# ATmega1281 register map
Vendor: Atmel; File version: 1.0
CPU: other r0p0, little endian, no MPU, no FPU, 4 interrupt priority bits
Registers are 8-bit, read-write, reset 0x0 unless marked. A register's access mark holds for its fields unless they carry their own. Offsets are from the block's base; [hi:lo] are bit positions.

## TC5 — Timer/Counter, 16-bit
Base 0x0080003A
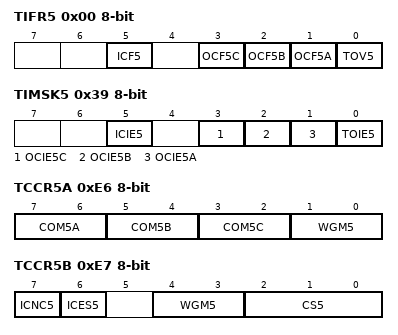
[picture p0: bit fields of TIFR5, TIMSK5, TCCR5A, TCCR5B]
0x00 TIFR5 — Timer/Counter5 Interrupt Flag register (write-only for debugger)
  [5] ICF5 — Input Capture Flag 5
  [3] OCF5C — Output Compare Flag 5C
  [2] OCF5B — Output Compare Flag 5B
  [1] OCF5A — Output Compare Flag 5A
  [0] TOV5 — Timer/Counter5 Overflow Flag
0x39 TIMSK5 — Timer/Counter5 Interrupt Mask Register
  [5] ICIE5 — Timer/Counter5 Input Capture Interrupt Enable
  [3] OCIE5C — Timer/Counter5 Output Compare C Match Interrupt Enable
  [2] OCIE5B — Timer/Counter5 Output Compare B Match Interrupt Enable
  [1] OCIE5A — Timer/Counter5 Output Compare A Match Interrupt Enable
  [0] TOIE5 — Timer/Counter5 Overflow Interrupt Enable
0xE6 TCCR5A — Timer/Counter5 Control Register A
  [7:6] COM5A — Compare Output Mode 1A, bits
  [5:4] COM5B — Compare Output Mode 5B, bits
  [3:2] COM5C — Compare Output Mode 5C, bits
  [1:0] WGM5 — Waveform Generation Mode
0xE7 TCCR5B — Timer/Counter5 Control Register B
  [7] ICNC5 — Input Capture 5 Noise Canceler
  [6] ICES5 — Input Capture 5 Edge Select
  [4:3] WGM5 — Waveform Generation Mode
  [2:0] CS5 — Prescaler source of Timer/Counter 5
    0=NO_CLOCK_SOURCE_STOPPED; 1=RUNNING_NO_PRESCALING; 2=RUNNING_CLK_8; 3=RUNNING_CLK_64; 4=RUNNING_CLK_256; 5=RUNNING_CLK_1024; 6=RUNNING_EXTCLK_TN_FALLING_EDGE; 7=RUNNING_EXTCLK_TN_RISING_EDGE
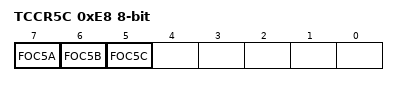
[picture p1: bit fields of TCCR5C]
0xE8 TCCR5C — Timer/Counter 5 Control Register C
  [7] FOC5A — Force Output Compare 5A
  [6] FOC5B — Force Output Compare 5B
  [5] FOC5C — Force Output Compare 5C
0xEA TCNT5 16-bit (reset mask 0xFF) — Timer/Counter5 Bytes
0xEC ICR5 16-bit (reset mask 0xFF) — Timer/Counter5 Input Capture Register Bytes
0xEE OCR5A 16-bit (reset mask 0xFF) — Timer/Counter5 Output Compare Register A Bytes
0xF0 OCR5B 16-bit (reset mask 0xFF) — Timer/Counter5 Output Compare Register B Bytes
0xF2 OCR5C 16-bit (reset mask 0xFF) — Timer/Counter5 Output Compare Register B Bytes

## TWI — Two Wire Serial Interface
Base 0x008000B8
0x00 TWBR — TWI Bit Rate register
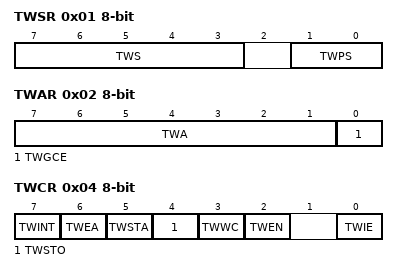
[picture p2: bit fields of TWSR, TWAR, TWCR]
0x01 TWSR — TWI Status Register
  [7:3] TWS — TWI Status
  [1:0] TWPS — TWI Prescaler
    0=1; 1=4; 2=16; 3=64
0x02 TWAR — TWI (Slave) Address register
  [7:1] TWA — TWI (Slave) Address register Bits
  [0] TWGCE — TWI General Call Recognition Enable Bit
0x03 TWDR — TWI Data register
0x04 TWCR — TWI Control Register (read-only for debugger)
  [7] TWINT — TWI Interrupt Flag
  [6] TWEA — TWI Enable Acknowledge Bit
  [5] TWSTA — TWI Start Condition Bit
  [4] TWSTO — TWI Stop Condition Bit
  [3] TWWC — TWI Write Collision Flag
  [2] TWEN — TWI Enable Bit
  [0] TWIE — TWI Interrupt Enable
0x05 TWAMR — TWI (Slave) Address Mask Register
  [7:1] TWAM

## USART0 — USART
Base 0x008000C0
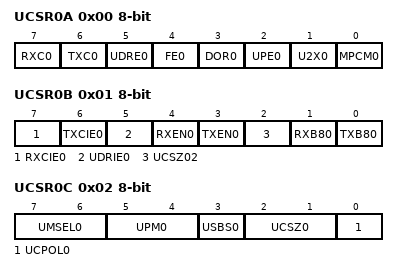
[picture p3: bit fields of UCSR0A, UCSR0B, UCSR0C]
0x00 UCSR0A — USART Control and Status Register A (read-only for debugger)
  [7] RXC0 ro — USART Receive Complete
  [6] TXC0 — USART Transmit Complete
  [5] UDRE0 ro — USART Data Register Empty
  [4] FE0 ro — Framing Error
  [3] DOR0 ro — Data overRun
  [2] UPE0 ro — Parity Error
  [1] U2X0 — Double the USART transmission speed
  [0] MPCM0 — Multi-processor Communication Mode
0x01 UCSR0B — USART Control and Status Register B
  [7] RXCIE0 — RX Complete Interrupt Enable
  [6] TXCIE0 — TX Complete Interrupt Enable
  [5] UDRIE0 — USART Data register Empty Interrupt Enable
  [4] RXEN0 — Receiver Enable
  [3] TXEN0 — Transmitter Enable
  [2] UCSZ02 — Character Size
  [1] RXB80 — Receive Data Bit 8
  [0] TXB80 — Transmit Data Bit 8
0x02 UCSR0C — USART Control and Status Register C
  [7:6] UMSEL0 — USART Mode Select
    0=ASYNCHRONOUS_USART; 1=SYNCHRONOUS_USART; 3=MASTER_SPI
  [5:4] UPM0 — Parity Mode Bits
    0=DISABLED; 2=ENABLED_EVEN_PARITY; 3=ENABLED_ODD_PARITY
  [3] USBS0 — Stop Bit Select
    0=1_BIT; 1=2_BIT
  [2:1] UCSZ0 — Character Size
  [0] UCPOL0 — Clock Polarity
0x04 UBRR0 16-bit (reset mask 0xFF) — USART Baud Rate Register Bytes
0x06 UDR0 — USART I/O Data Register (write-only for debugger)

## USART1 — USART
Base 0x008000C8
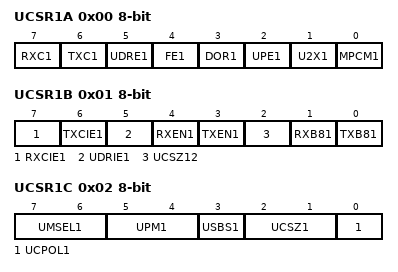
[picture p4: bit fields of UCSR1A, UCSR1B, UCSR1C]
0x00 UCSR1A — USART Control and Status Register A (read-only for debugger)
  [7] RXC1 — USART Receive Complete
  [6] TXC1 — USART Transmit Complete
  [5] UDRE1 — USART Data Register Empty
  [4] FE1 — Framing Error
  [3] DOR1 — Data overRun
  [2] UPE1 — Parity Error
  [1] U2X1 — Double the USART transmission speed
  [0] MPCM1 — Multi-processor Communication Mode
0x01 UCSR1B — USART Control and Status Register B
  [7] RXCIE1 — RX Complete Interrupt Enable
  [6] TXCIE1 — TX Complete Interrupt Enable
  [5] UDRIE1 — USART Data register Empty Interrupt Enable
  [4] RXEN1 — Receiver Enable
  [3] TXEN1 — Transmitter Enable
  [2] UCSZ12 — Character Size
  [1] RXB81 — Receive Data Bit 8
  [0] TXB81 — Transmit Data Bit 8
0x02 UCSR1C — USART Control and Status Register C
  [7:6] UMSEL1 — USART Mode Select
    0=ASYNCHRONOUS_USART; 1=SYNCHRONOUS_USART; 3=MASTER_SPI
  [5:4] UPM1 — Parity Mode Bits
    0=DISABLED; 2=ENABLED_EVEN_PARITY; 3=ENABLED_ODD_PARITY
  [3] USBS1 — Stop Bit Select
    0=1_BIT; 1=2_BIT
  [2:1] UCSZ1 — Character Size
  [0] UCPOL1 — Clock Polarity
0x04 UBRR1 16-bit (reset mask 0xFF) — USART Baud Rate Register Bytes
0x06 UDR1 — USART I/O Data Register (write-only for debugger)

## WDT — Watchdog Timer
Base 0x00800060
0x00 WDTCSR — Watchdog Timer Control Register (read-only for debugger)
  [7] WDIF — Watchdog Timeout Interrupt Flag
  [6] WDIE — Watchdog Timeout Interrupt Enable
  [4] WDCE — Watchdog Change Enable
  [3] WDE — Watch Dog Enable
  [5:0] WDP — Watchdog Timer Prescaler Bits
    0=OSCILLATOR_CYCLES_2K; 1=OSCILLATOR_CYCLES_4K; 2=OSCILLATOR_CYCLES_8K; 3=OSCILLATOR_CYCLES_16K; 4=OSCILLATOR_CYCLES_32K; 5=OSCILLATOR_CYCLES_64K; 6=OSCILLATOR_CYCLES_128K; 7=OSCILLATOR_CYCLES_256K
